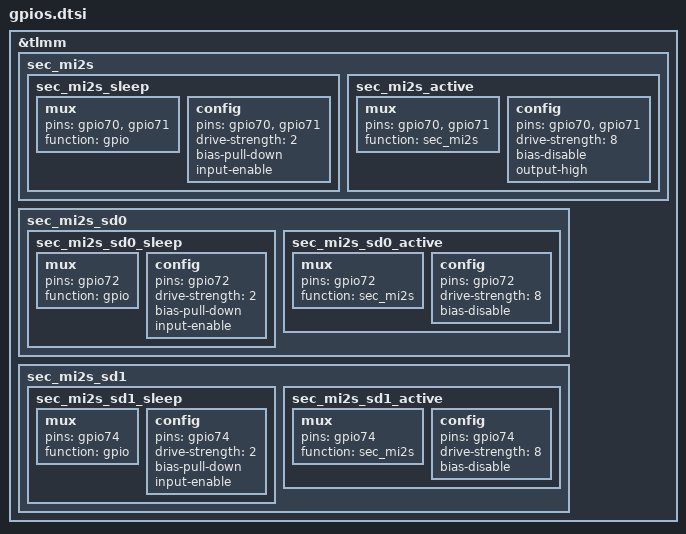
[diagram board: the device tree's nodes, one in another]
/*
 * nubia overwrite dts
 */

&tlmm {
        sec_mi2s {
		sec_mi2s_sleep: sec_mi2s_sleep {
			mux {
				pins = "gpio70", "gpio71";
				function = "gpio";
			};

			config {
				pins = "gpio70", "gpio71";
				drive-strength = <2>;   /* 2 mA */
				bias-pull-down;         /* PULL DOWN */
				input-enable;
			};
		};

		sec_mi2s_active: sec_mi2s_active {
			mux {
				pins = "gpio70", "gpio71";
				function = "sec_mi2s";
			};

			config {
				pins = "gpio70", "gpio71";
				drive-strength = <8>;   /* 8 mA */
				bias-disable;           /* NO PULL */
				output-high;
			};
		};
	};

	sec_mi2s_sd0 {
		sec_mi2s_sd0_sleep: sec_mi2s_sd0_sleep {
			mux {
				pins = "gpio72";
				function = "gpio";
			};

			config {
				pins = "gpio72";
				drive-strength = <2>;   /* 2 mA */
				bias-pull-down;         /* PULL DOWN */
				input-enable;
			};
		};

		sec_mi2s_sd0_active: sec_mi2s_sd0_active {
			mux {
				pins = "gpio72";
				function = "sec_mi2s";
			};

			config {
				pins = "gpio72";
				drive-strength = <8>;   /* 8 mA */
				bias-disable;           /* NO PULL */
			};
		};
	};

	sec_mi2s_sd1 {
		sec_mi2s_sd1_sleep: sec_mi2s_sd1_sleep {
			mux {
				pins = "gpio74";
				function = "gpio";
			};

			config {
				pins = "gpio74";
				drive-strength = <2>;   /* 2 mA */
				bias-pull-down;         /* PULL DOWN */
				input-enable;
			};
		};

		sec_mi2s_sd1_active: sec_mi2s_sd1_active {
			mux {
				pins = "gpio74";
				function = "sec_mi2s";
			};

			config {
				pins = "gpio74";
				drive-strength = <8>;   /* 8 mA */
				bias-disable;           /* NO PULL */
			};
                };
        };
};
